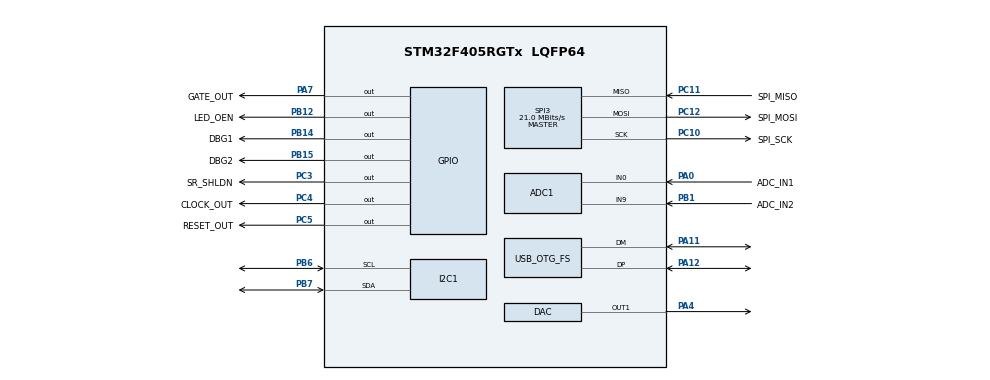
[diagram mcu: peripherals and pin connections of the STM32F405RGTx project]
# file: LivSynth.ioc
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ADC1.Channel-0\#ChannelRegularConversion=ADC_CHANNEL_0
ADC1.Channel-1\#ChannelRegularConversion=ADC_CHANNEL_9
ADC1.ContinuousConvMode=ENABLE
ADC1.DMAContinuousRequests=ENABLE
ADC1.NbrOfConversion=2
ADC1.NbrOfConversionFlag=1
ADC1.Rank-0\#ChannelRegularConversion=1
ADC1.Rank-1\#ChannelRegularConversion=2
ADC1.SamplingTime-0\#ChannelRegularConversion=ADC_SAMPLETIME_480CYCLES
ADC1.SamplingTime-1\#ChannelRegularConversion=ADC_SAMPLETIME_480CYCLES
ADC1.ScanConvMode=ENABLE
ADC1.master=1
Dma.ADC1.0.Direction=DMA_PERIPH_TO_MEMORY
Dma.ADC1.0.FIFOMode=DMA_FIFOMODE_DISABLE
Dma.ADC1.0.Instance=DMA2_Stream0
Dma.ADC1.0.MemDataAlignment=DMA_MDATAALIGN_HALFWORD
Dma.ADC1.0.MemInc=DMA_MINC_ENABLE
Dma.ADC1.0.Mode=DMA_CIRCULAR
Dma.ADC1.0.PeriphDataAlignment=DMA_PDATAALIGN_HALFWORD
Dma.ADC1.0.PeriphInc=DMA_PINC_DISABLE
Dma.ADC1.0.Priority=DMA_PRIORITY_LOW
Dma.I2C1_TX.1.Direction=DMA_MEMORY_TO_PERIPH
Dma.I2C1_TX.1.FIFOMode=DMA_FIFOMODE_DISABLE
Dma.I2C1_TX.1.Instance=DMA1_Stream6
Dma.I2C1_TX.1.MemDataAlignment=DMA_MDATAALIGN_BYTE
Dma.I2C1_TX.1.MemInc=DMA_MINC_ENABLE
Dma.I2C1_TX.1.Mode=DMA_NORMAL
Dma.I2C1_TX.1.PeriphDataAlignment=DMA_PDATAALIGN_BYTE
Dma.I2C1_TX.1.PeriphInc=DMA_PINC_DISABLE
Dma.I2C1_TX.1.Priority=DMA_PRIORITY_LOW
Dma.Request0=ADC1
Dma.Request1=I2C1_TX
Mcu.Family=STM32F4
Mcu.Name=STM32F405RGTx
Mcu.Package=LQFP64
NVIC.DMA1_Stream6_IRQn=true\:4\:0\:true\:false\:true\:false\:true\:true
NVIC.DMA2_Stream0_IRQn=true\:3\:0\:true\:false\:true\:false\:true\:true
NVIC.OTG_FS_IRQn=true\:2\:0\:true\:false\:true\:false\:true\:true
NVIC.PriorityGroup=NVIC_PRIORITYGROUP_4
NVIC.TIM5_IRQn=true\:1\:0\:true\:false\:true\:true\:true\:true
PA0-WKUP.GPIO_Label=ADC_IN1
PA0-WKUP.Signal=ADCx_IN0
PA11.Mode=Device_Only
PA11.Signal=USB_OTG_FS_DM
PA12.Mode=Device_Only
PA12.Signal=USB_OTG_FS_DP
PA13.Mode=Trace_Asynchronous_SW
PA13.Signal=SYS_JTMS-SWDIO
PA14.Mode=Trace_Asynchronous_SW
PA14.Signal=SYS_JTCK-SWCLK
PA4.Signal=COMP_DAC1_group
PA7.GPIO_Label=GATE_OUT
PA7.Signal=GPIO_Output
PB1.GPIO_Label=ADC_IN2
PB1.Signal=ADCx_IN9
PB12.GPIO_Label=LED_OEN
PB12.Signal=GPIO_Output
PB14.GPIO_Label=DBG1
PB14.Signal=GPIO_Output
PB15.GPIO_Label=DBG2
PB15.Signal=GPIO_Output
PB3.Mode=Trace_Asynchronous_SW
PB3.Signal=SYS_JTDO-SWO
PB6.Mode=I2C
PB6.Signal=I2C1_SCL
PB7.Mode=I2C
PB7.Signal=I2C1_SDA
PC10.GPIO_Label=SPI_SCK
PC10.Mode=Full_Duplex_Master
PC10.Signal=SPI3_SCK
PC11.GPIO_Label=SPI_MISO
PC11.Mode=Full_Duplex_Master
PC11.Signal=SPI3_MISO
PC12.GPIO_Label=SPI_MOSI
PC12.Mode=Full_Duplex_Master
PC12.Signal=SPI3_MOSI
PC3.GPIO_Label=SR_SHLDN
PC3.Signal=GPIO_Output
PC4.GPIO_Label=CLOCK_OUT
PC4.Signal=GPIO_Output
PC5.GPIO_Label=RESET_OUT
PC5.Signal=GPIO_Output
PH0-OSC_IN.Mode=HSE-External-Oscillator
PH0-OSC_IN.Signal=RCC_OSC_IN
PH1-OSC_OUT.Mode=HSE-External-Oscillator
PH1-OSC_OUT.Signal=RCC_OSC_OUT
ProjectManager.HeapSize=0x200
ProjectManager.StackSize=0x400
ProjectManager.TargetToolchain=STM32CubeIDE
RCC.48MHZClocksFreq_Value=48000000
RCC.AHBFreq_Value=168000000
RCC.APB1CLKDivider=RCC_HCLK_DIV4
RCC.APB1Freq_Value=42000000
RCC.APB1TimFreq_Value=84000000
RCC.APB2CLKDivider=RCC_HCLK_DIV2
RCC.APB2Freq_Value=84000000
RCC.APB2TimFreq_Value=168000000
RCC.CortexFreq_Value=168000000
RCC.HCLKFreq_Value=168000000
RCC.HSE_VALUE=16000000
RCC.HSI_VALUE=16000000
RCC.LSE_VALUE=32768
RCC.PLLM=8
RCC.PLLN=168
RCC.PLLQ=7
RCC.SYSCLKFreq_VALUE=168000000
RCC.SYSCLKSource=RCC_SYSCLKSOURCE_PLLCLK
RCC.VCOOutputFreq_Value=336000000
SH.ADCx_IN0.0=ADC1_IN0,IN0
SH.ADCx_IN9.0=ADC1_IN9,IN9
SH.COMP_DAC1_group.0=DAC_OUT1,DAC_OUT1
SPI3.BaudRatePrescaler=SPI_BAUDRATEPRESCALER_2
SPI3.CalculateBaudRate=21.0 MBits/s
SPI3.DataSize=SPI_DATASIZE_16BIT
SPI3.Direction=SPI_DIRECTION_2LINES
SPI3.Mode=SPI_MODE_MASTER
SPI3.VirtualType=VM_MASTER
TIM5.Period=2603
TIM5.Prescaler=83
USB_DEVICE.CLASS_NAME_FS=CDC
USB_DEVICE.CONFIGURATION_STRING_CDC_FS=S54 Config
USB_DEVICE.INTERFACE_STRING_CDC_FS=S54 Interface
USB_DEVICE.MANUFACTURER_STRING-CDC_FS=SloBlo Labs
USB_DEVICE.PID_CDC_FS=21156
USB_DEVICE.PRODUCT_STRING_CDC_FS=S54 (Liv's Synth)
USB_DEVICE.VirtualMode-CDC_FS=Cdc
USB_DEVICE.VirtualModeFS=Cdc_FS
USB_OTG_FS.VirtualMode=Device_Only
VP_TIM5_VS_ClockSourceINT.Mode=Internal
VP_USB_DEVICE_VS_USB_DEVICE_CDC_FS.Mode=CDC_FS
board=custom

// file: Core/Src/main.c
/* USER CODE BEGIN Header */
/**
  ******************************************************************************
  * @file           : main.c
  * @brief          : Main program body
  ******************************************************************************
  * @attention
  *
  * Copyright (c) 2022 STMicroelectronics.
  * All rights reserved.
  *
  * This software is licensed under terms that can be found in the LICENSE file
  * in the root directory of this software component.
  * If no LICENSE file comes with this software, it is provided AS-IS.
  *
  ******************************************************************************
  */
/* USER CODE END Header */
#include "main.h"
#include "adc.h"
#include "dac.h"
#include "dma.h"
#include "i2c.h"
#include "spi.h"
#include "tim.h"
#include "usb_device.h"
#include "gpio.h"

/* USER CODE BEGIN Includes */
#include "LivSynthMain.h"
/* USER CODE END Includes */

void SystemClock_Config(void);

int main(void)
{

  /* MCU Configuration--------------------------------------------------------*/

  /* Reset of all peripherals, Initializes the Flash interface and the Systick. */
  HAL_Init();

  /* Configure the system clock */
  SystemClock_Config();

  /* Initialize all configured peripherals */
  MX_GPIO_Init();
  MX_DMA_Init();
  MX_USB_DEVICE_Init();
  MX_ADC1_Init();
  MX_DAC_Init();
  MX_TIM5_Init();
  MX_I2C1_Init();
  MX_SPI3_Init();

  /* Infinite loop */
  /* USER CODE BEGIN WHILE */
  appMain();
  while (1)
  {
    printf("Hello!\n");
    LL_mDelay(100);
    /* USER CODE END WHILE */

  }
}

void SystemClock_Config(void)
{
  LL_FLASH_SetLatency(LL_FLASH_LATENCY_5);
  while(LL_FLASH_GetLatency()!= LL_FLASH_LATENCY_5)
  {
  }
  LL_PWR_SetRegulVoltageScaling(LL_PWR_REGU_VOLTAGE_SCALE1);
  LL_RCC_HSE_Enable();

   /* Wait till HSE is ready */
  while(LL_RCC_HSE_IsReady() != 1)
  {

  }
  LL_RCC_PLL_ConfigDomain_SYS(LL_RCC_PLLSOURCE_HSE, LL_RCC_PLLM_DIV_8, 168, LL_RCC_PLLP_DIV_2);
  LL_RCC_PLL_ConfigDomain_48M(LL_RCC_PLLSOURCE_HSE, LL_RCC_PLLM_DIV_8, 168, LL_RCC_PLLQ_DIV_7);
  LL_RCC_PLL_Enable();

   /* Wait till PLL is ready */
  while(LL_RCC_PLL_IsReady() != 1)
  {

  }
  while (LL_PWR_IsActiveFlag_VOS() == 0)
  {
  }
  LL_RCC_SetAHBPrescaler(LL_RCC_SYSCLK_DIV_1);
  LL_RCC_SetAPB1Prescaler(LL_RCC_APB1_DIV_4);
  LL_RCC_SetAPB2Prescaler(LL_RCC_APB2_DIV_2);
  LL_RCC_SetSysClkSource(LL_RCC_SYS_CLKSOURCE_PLL);

   /* Wait till System clock is ready */
  while(LL_RCC_GetSysClkSource() != LL_RCC_SYS_CLKSOURCE_STATUS_PLL)
  {

  }
  LL_SetSystemCoreClock(168000000);

   /* Update the time base */
  if (HAL_InitTick (TICK_INT_PRIORITY) != HAL_OK)
  {
    Error_Handler();
  }
}

void Error_Handler(void)
{
  __disable_irq();
  while (1)
  {
  }
}
